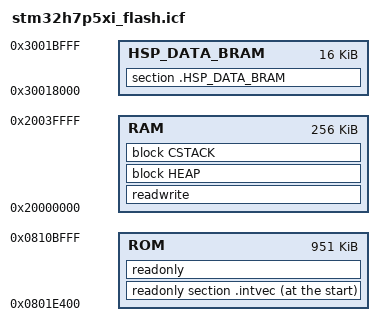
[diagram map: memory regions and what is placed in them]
/**
******************************************************************************
* @file    stm32h7p5xi_flash.icf
* @brief   Linker File
******************************************************************************
* @attention
*
* Copyright (c) 2026 STMicroelectronics.
* All rights reserved.
*
* This software is licensed under terms that can be found in the LICENSE file
* in the root directory of this software component.
* If no LICENSE file comes with this software, it is provided AS-IS.
*
******************************************************************************
*/

/* Do not edit ROM_APPLI_xxxxxx definitions, updated by the provisioning scripts */
define symbol ROM_APPLI_ADDRESS               = 0x801E400;
define symbol ROM_APPLI_SIZE                  = 0xEDC00;

define symbol RAM_APPLI_ADDRESS               = 0x20000000;
define symbol RAM_APPLI_SIZE                  = 0x40000;

define symbol __ICFEDIT_intvec_start__        = ROM_APPLI_ADDRESS;

define symbol __ICFEDIT_size_cstack__         = 0x400;

define memory mem with size = 4G;
define region ROM = mem:[from ROM_APPLI_ADDRESS size ROM_APPLI_SIZE];
define region RAM = mem:[from RAM_APPLI_ADDRESS size RAM_APPLI_SIZE];
define region HSP_DATA_BRAM = mem:[from 0x30018000 size 0x4000];

/* define blocks */
define block HEAP with alignment = 8, size = 0x200 { };
define block CSTACK with alignment = 8, size = 0x400 { };

/* setup initialization strategies */
initialize by copy {
  readwrite
};

do not initialize {
  section .noinit,
  section .HSP_DATA_BRAM
};

place at start of ROM { readonly section .intvec } ;

/* sections placements */
place in ROM {
  readonly
};

place in RAM {
  readwrite,
  block HEAP,
  block CSTACK
};

place in HSP_DATA_BRAM {
  section .HSP_DATA_BRAM
};
